# MKW38A4 register map
Vendor: NXP Semiconductors; Series: Kinetis_W; File version: 1.6
CPU: CM0PLUS r0p0, little endian, no MPU, no FPU, VTOR, 2 interrupt priority bits
Registers are 32-bit, read-write, no defined reset value unless marked. A register's access mark holds for its fields unless they carry their own. Offsets are from the block's base; [hi:lo] are bit positions; {n}, {i} and the like mark numbered series.

## XCVR_2P4GHZ_PHY — 2.4GHz PHY REGISTERS
Base 0x40087800
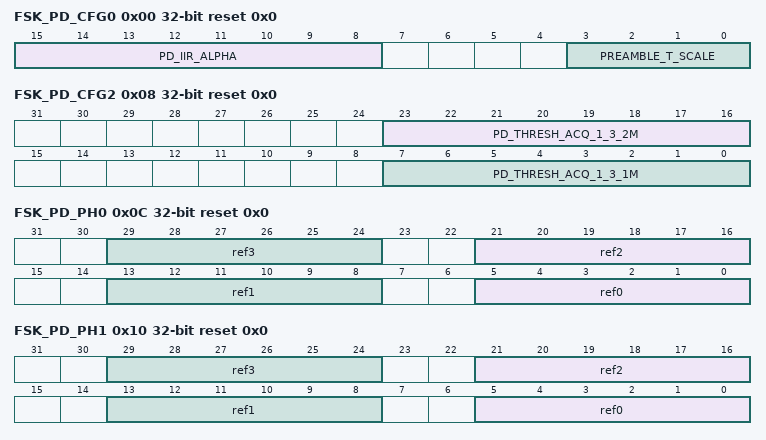
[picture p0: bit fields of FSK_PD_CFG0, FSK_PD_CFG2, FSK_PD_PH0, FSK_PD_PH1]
0x00 FSK_PD_CFG0 reset 0x0 — PHY Uncoded Preamble Detect Config 0
  [15:8] PD_IIR_ALPHA — Forgetting factor used by the complex correlations smoothing leaky integrator.
  [3:0] PREAMBLE_T_SCALE — Scaling factor used for fractional time estimation during preamble search.
0x04 FSK_PD_CFG1 reset 0x0 — PHY Uncoded Preamble Detect Config 1
  [7:0] PREAMBLE_PATTERN — 8-bit preamble pattern used in FM-domain preamble detector.
0x08 FSK_PD_CFG2 reset 0x0 — PHY Uncoded Preamble Detect Config 2
  [23:16] PD_THRESH_ACQ_1_3_2M — Preamble detect threshold for acq mode 1 and 3 at data rate 2Mbps
  [7:0] PD_THRESH_ACQ_1_3_1M — Preamble detect threshold for acq mode 1 and 3 at data rate 1Mbps
0x0C FSK_PD_PH0 reset 0x0
  [8n+5:8n] ref{n} (n=0..3) — Uncoded preamble reference waveform sample {n} (sfix6en5)
0x10 FSK_PD_PH1 reset 0x0
  [8n+5:8n] ref{n} (n=0..3) — Uncoded preamble reference waveform sample {n+4} (sfix6en5)
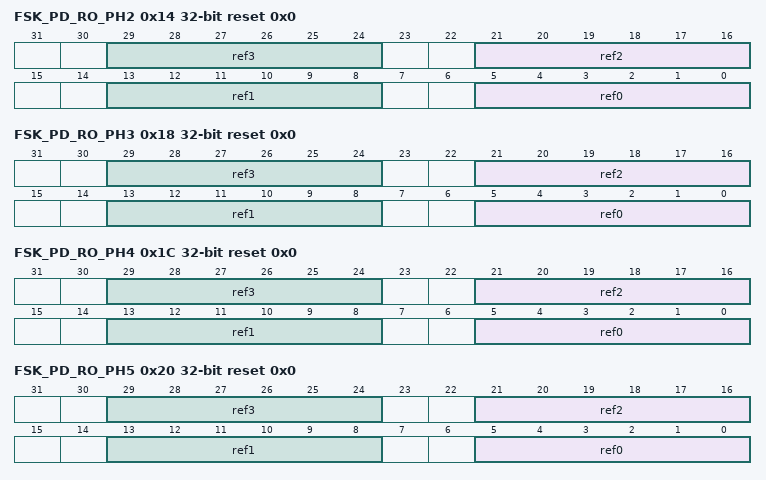
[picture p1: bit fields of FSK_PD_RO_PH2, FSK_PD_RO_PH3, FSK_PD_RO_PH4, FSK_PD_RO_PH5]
0x14 FSK_PD_RO_PH2 ro reset 0x0
  [8n+5:8n] ref{n} (n=0..3) — Uncoded preamble reference waveform sample {n+16} (sfix6en5)
0x18 FSK_PD_RO_PH3 ro reset 0x0
  [8n+5:8n] ref{n} (n=0..3) — Uncoded preamble reference waveform sample {n+20} (sfix6en5)
0x1C FSK_PD_RO_PH4 ro reset 0x0
  [8n+5:8n] ref{n} (n=0..3) — Uncoded preamble reference waveform sample {n+24} (sfix6en5)
0x20 FSK_PD_RO_PH5 ro reset 0x0
  [8n+5:8n] ref{n} (n=0..3) — Uncoded preamble reference waveform sample {n+28} (sfix6en5)
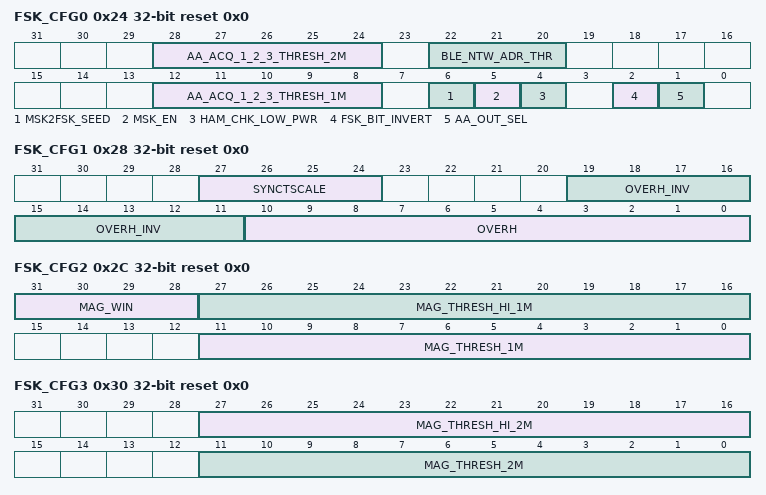
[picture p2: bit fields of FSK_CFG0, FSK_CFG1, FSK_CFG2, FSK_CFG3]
0x24 FSK_CFG0 reset 0x0 — PHY Uncoded Config 0
  [28:24] AA_ACQ_1_2_3_THRESH_2M — For 2Mbps data rate, correlation threshold applicable to AA detection; uses ufix5_En5 fixed-point format.
  [22:20] BLE_NTW_ADR_THR — Maximum hamming distance from the given AA pattern that may still be accepted as a match; valid range [0,7].
  [12:8] AA_ACQ_1_2_3_THRESH_1M — For 1Mbps data rate, Correlation threshold applicable to AA detection; uses ufix5_En5 fixed-point format.
  [6] MSK2FSK_SEED — Last bit of preamble.
  [5] MSK_EN — Configures PHY for MSK decoding.
  [4] HAM_CHK_LOW_PWR — Indicates whether hamming-distance check is applied at signal levels below mag_thresh_high;
    0=no; 1=yes
  [2] FSK_BIT_INVERT — This applies at the demodulator, so it affects both AA and the data portions of the packet.
    0=Normal demodulation; 1=Invert demodulated bits
  [1] AA_OUT_SEL — Specifies which AA bits to be played-back to the LL:
    0=output the received AA bits; 1=output the programmed AA bits
0x28 FSK_CFG1 reset 0x0 — PHY Uncoded Config 1
  [27:24] SYNCTSCALE — Scaling factor used for fractional time estimation during AA search; represented in ufix4_En3 format.
  [19:11] OVERH_INV — Reciprocal of modulation index; represented in ufix9_En7 format.
  [10:0] OVERH — Modulation index; represented in ufix11_En7 format.
0x2C FSK_CFG2 reset 0x0 — PHY Uncoded Config 2
  [31:28] MAG_WIN — Indicates the forgetting factor used in received signal level measurement;
  [27:16] MAG_THRESH_HI_1M — For 1Mbps data rate, the lowest signal level above which hamming-distance is always checked during AA detection; uses ufix12_En24 fixed-point format.
  [11:0] MAG_THRESH_1M — For 1Mbps data rate, the lowest signal level below which synchronization is considered unreliable and hence disallowed; uses ufix12_En24 fixed-point format.
0x30 FSK_CFG3 reset 0x0 — PHY Uncoded Config 3
  [27:16] MAG_THRESH_HI_2M — For 2Mbps data rate, the lowest signal level above which hamming-distance is always checked during AA detection; uses ufix12_En24 fixed-point format.
  [11:0] MAG_THRESH_2M — For 2Mbps data rate, the lowest signal level below which synchronization is considered unreliable and hence disallowed; uses ufix12_En24 fixed-point format.
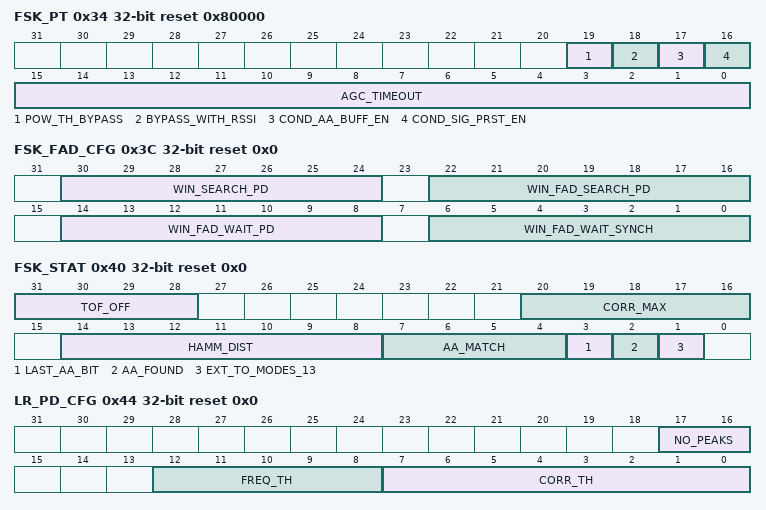
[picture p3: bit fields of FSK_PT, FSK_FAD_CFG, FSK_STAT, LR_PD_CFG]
0x34 FSK_PT reset 0x80000 — PHY Uncoded Power Threshold Config
  [19] POW_TH_BYPASS — Bypass power threshold when AGC gain are not set max;
    0=no bypass; 1=yes bypass
  [18] BYPASS_WITH_RSSI — Bypass signal power measurement with RSSI measurement;
    0=no; 1=yes
  [17] COND_AA_BUFF_EN — Enables special condition for enabling AA detector buffer;
    0=disable; 1=enable
  [16] COND_SIG_PRST_EN — Enables special conditioning of signal detection;
    0=disable; 1=enable
  [15:0] AGC_TIMEOUT — Time-out, applicable to special conditioning of signal power detection in the Power threshold block, after each AGC gain adjustment. It is expressed in number of samples.
0x38 FSK_FAD_CTRL reset 0x0 — PHY Uncoded FAD Control
  [0] FAD_EN — Enables FAD;
    0=disable; 1=enable
0x3C FSK_FAD_CFG reset 0x0 — PHY Uncoded FAD Config
  [30:24] WIN_SEARCH_PD — Time-window to match preamble pattern on samples coming from the currently selected antenna (refered to as T0 in the PHY state-machine section).
  [22:16] WIN_FAD_SEARCH_PD — Time-window to match preamble pattern on samples coming from the previously selected antenna (refered to as T1 in the PHY state-machine section).
  [14:8] WIN_FAD_WAIT_PD — Time-window to wait for clean samples if PD was not found after antenna switch (refered to as T2 in the PHY state-machine section).
  [6:0] WIN_FAD_WAIT_SYNCH — Time-window to wait for clean samples, before transitioning to AA search PHY state, if PD was found after antenna switch (refered to as T3 in the PHY state-machine section).
0x40 FSK_STAT ro reset 0x0 — PHY Uncoded Status
  [31:28] TOF_OFF — Timing offset for use in time-of-flight calculation.
  [20:16] CORR_MAX — Indicates the correlation witnessed when AA match occurred
  [14:8] HAMM_DIST — Indicates the hamming distance witnessed when AA match occurred.
  [7:4] AA_MATCH — Indicates which non-coded AA has matched. This will clear when the PHY is re-initialized.
  [3] LAST_AA_BIT — reserved
  [2] AA_FOUND — Indicates that a uncoded AA detect is active.
  [1] EXT_TO_MODES_13 — Reserved
0x44 LR_PD_CFG reset 0x0 — PHY Long Range Preamble Detect Config
  [17:16] NO_PEAKS — Number of consecutive correlation values that have to exceed the PD correlation threshold,for the same preamble phase, to assert preamble found;
    {v}={v+2} peaks; (v=0..3)
  [12:8] FREQ_TH — Threshold used to compare CFO estimates in the LR preamble detector; uses ufix5_En5 format.
  [7:0] CORR_TH — Correlation threshold applicable to preamble detection; uses (0,8,8) fixed-point format.
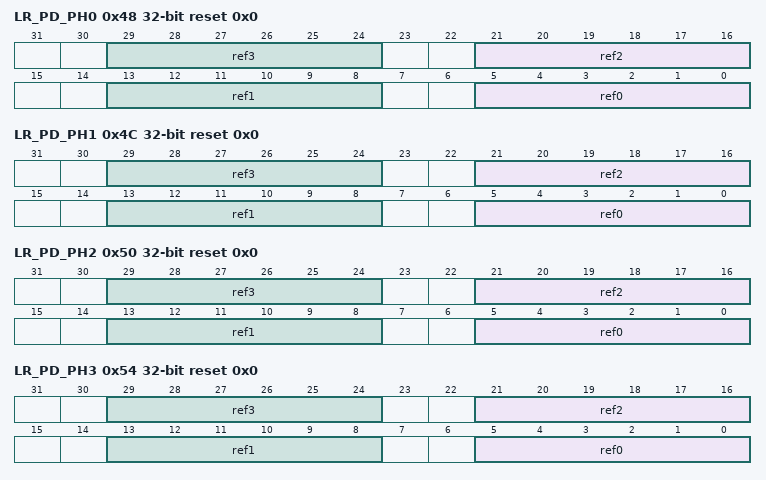
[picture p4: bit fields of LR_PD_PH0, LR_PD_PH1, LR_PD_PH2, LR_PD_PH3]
0x48 LR_PD_PH0 reset 0x0
  [8n+5:8n] ref{n} (n=0..3) — Long range preamble reference waveform sample {n} (sfix6en5)
0x4C LR_PD_PH1 reset 0x0
  [8n+5:8n] ref{n} (n=0..3) — Long range preamble reference waveform sample {n+4} (sfix6en5)
0x50 LR_PD_PH2 reset 0x0
  [8n+5:8n] ref{n} (n=0..3) — Long range preamble reference waveform sample {n+8} (sfix6en5)
0x54 LR_PD_PH3 reset 0x0
  [8n+5:8n] ref{n} (n=0..3) — Long range preamble reference waveform sample {n+12} (sfix6en5)
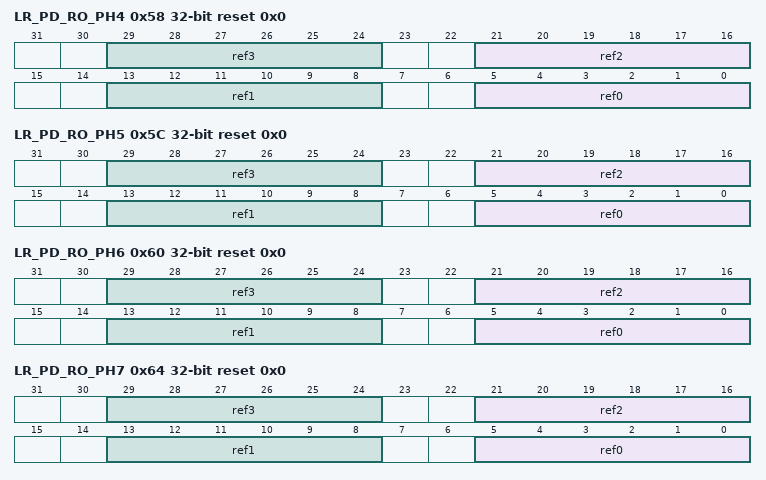
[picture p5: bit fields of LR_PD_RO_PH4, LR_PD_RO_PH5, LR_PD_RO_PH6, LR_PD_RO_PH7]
0x58 LR_PD_RO_PH4 ro reset 0x0
  [8n+5:8n] ref{n} (n=0..3) — Long range preamble reference waveform sample {n+16} (sfix6en5)
0x5C LR_PD_RO_PH5 ro reset 0x0
  [8n+5:8n] ref{n} (n=0..3) — Long range preamble reference waveform sample {n+20} (sfix6en5)
0x60 LR_PD_RO_PH6 ro reset 0x0
  [8n+5:8n] ref{n} (n=0..3) — Long range preamble reference waveform sample {n+24} (sfix6en5)
0x64 LR_PD_RO_PH7 ro reset 0x0
  [8n+5:8n] ref{n} (n=0..3) — Long range preamble reference waveform sample {n+28} (sfix6en5)
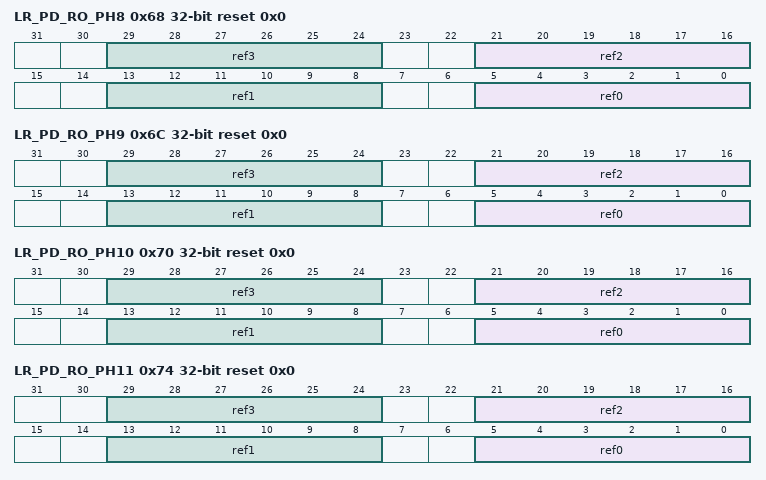
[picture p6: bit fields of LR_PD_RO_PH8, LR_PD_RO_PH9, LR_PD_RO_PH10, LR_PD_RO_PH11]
0x68 LR_PD_RO_PH8 ro reset 0x0
  [8n+5:8n] ref{n} (n=0..3) — Long range preamble reference waveform sample {n+32} (sfix6en5)
0x6C LR_PD_RO_PH9 ro reset 0x0
  [8n+5:8n] ref{n} (n=0..3) — Long range preamble reference waveform sample {n+36} (sfix6en5)
0x70 LR_PD_RO_PH10 ro reset 0x0
  [8n+5:8n] ref{n} (n=0..3) — Long range preamble reference waveform sample {n+40} (sfix6en5)
0x74 LR_PD_RO_PH11 ro reset 0x0
  [8n+5:8n] ref{n} (n=0..3) — Long range preamble reference waveform sample {n+44} (sfix6en5)
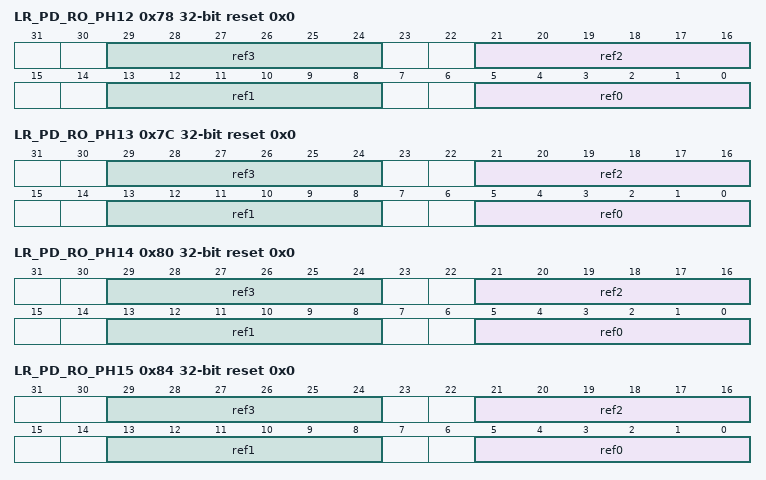
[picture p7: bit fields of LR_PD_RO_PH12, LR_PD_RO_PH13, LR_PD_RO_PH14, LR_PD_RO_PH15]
0x78 LR_PD_RO_PH12 ro reset 0x0
  [8n+5:8n] ref{n} (n=0..3) — Long range preamble reference waveform sample {n+48} (sfix6en5)
0x7C LR_PD_RO_PH13 ro reset 0x0
  [8n+5:8n] ref{n} (n=0..3) — Long range preamble reference waveform sample {n+52} (sfix6en5)
0x80 LR_PD_RO_PH14 ro reset 0x0
  [8n+5:8n] ref{n} (n=0..3) — Long range preamble reference waveform sample {n+56} (sfix6en5)
0x84 LR_PD_RO_PH15 ro reset 0x0
  [8n+5:8n] ref{n} (n=0..3) — Long range preamble reference waveform sample {n+60} (sfix6en5)
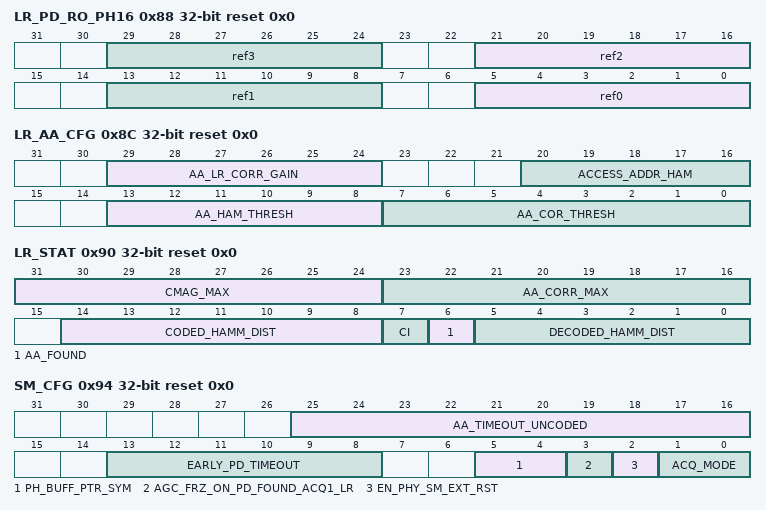
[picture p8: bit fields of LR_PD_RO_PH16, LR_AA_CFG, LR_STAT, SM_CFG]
0x88 LR_PD_RO_PH16 ro reset 0x0
  [8n+5:8n] ref{n} (n=0..3) — Long range preamble reference waveform sample {n+64} (sfix6en5)
0x8C LR_AA_CFG reset 0x0 — PHY Long Range AA Config
  [29:24] AA_LR_CORR_GAIN — AA correlator gain. Format ufix6en3. This gain is applied to soft bits from the demodulator before they are used for address search synchronization.
  [20:16] ACCESS_ADDR_HAM — Threshold use to compare the Hamming distance, between the reference AA sequence and the received Viterbi decoded AA sequence.
  [13:8] AA_HAM_THRESH — Threshold use to compare the Hamming distance, between reference coded sequence and received coded sequence, in the long-range AA correlator.
  [7:0] AA_COR_THRESH — Threshold use to compare the correlation magnitude in the long-range AA correlator.
0x90 LR_STAT ro reset 0x0 — PHY Long Range Status
  [31:24] CMAG_MAX — Indicates the maximum preamble correlation magnitude during preamble found
  [23:16] AA_CORR_MAX — Indicates the AA correlation magnitude witnessed when AA match occurred
  [14:8] CODED_HAMM_DIST — Hamming distance between the coded reference sequence and the coded received sequence.
  [7] CI — CI received.
  [6] AA_FOUND — Indicates that a AA detect is active for both LR and uncoded.
  [5:0] DECODED_HAMM_DIST — Hamming distance between the reference sequence and the Viterbi decoded received sequence
0x94 SM_CFG reset 0x0 — PHY State Machine Config
  [25:16] AA_TIMEOUT_UNCODED — Time-out value for access address search for uncoded packets
  [13:8] EARLY_PD_TIMEOUT — Time-out used to reset the AGC state-machine for the eventuality that an "PD found early" event occurs but it is not followed by an "PD found" event
  [5:4] PH_BUFF_PTR_SYM — Phase buffer size to demodulator, long range only.
  [3] AGC_FRZ_ON_PD_FOUND_ACQ1_LR — Specfies AGC freeze condition for non-coded acq.1 and Bluetooth LE long range.
    0=AGC freeze on AA found; 1=AGC freeze asserted on PD found
  [2] EN_PHY_SM_EXT_RST — Reserved, should keep 0.
  [1:0] ACQ_MODE — Acquisition mode for non-coded reception
    1=Use preamble and verify a correlation peak, the synch at the symbol rate as symbol timing is established by the preamble acquisition; 2=Use synch only (which may incorporate part of the preamble); 3=Use mainly the sync detection: Use a low threshold on the preamble detector and launch the synch detection only if the preamble has shown a recent peak
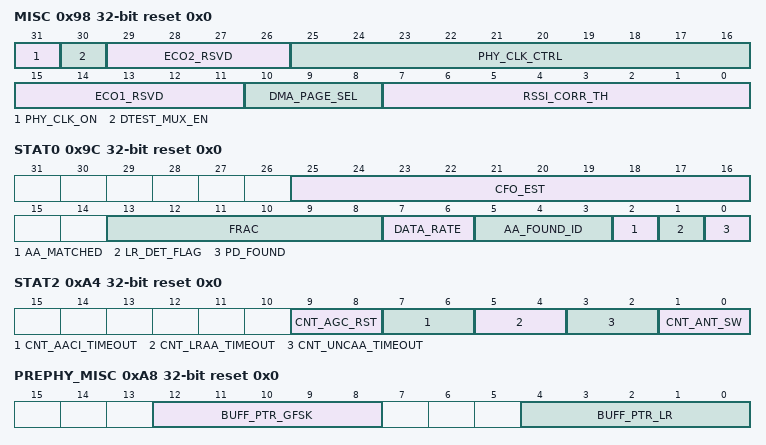
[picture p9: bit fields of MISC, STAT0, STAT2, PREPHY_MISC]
0x98 MISC reset 0x0 — PHY Misc Config
  [31] PHY_CLK_ON — Force PHY clock ON
  [30] DTEST_MUX_EN — Reserved. Should be programed as reset value 0.
  [29:26] ECO2_RSVD — Reserved
  [25:16] PHY_CLK_CTRL — Enables various clock gating features. Bits are individually decoded, so any combination is allowable.
  [15:11] ECO1_RSVD — Reserved. Must be programed as reset value 0.
  [10:8] DMA_PAGE_SEL — Select which DMA page is send out
    0=Select DMA PAGE 0 for M3C with cfo;; 1=Select DMA PAGE 1 for M3C with magnitude;; 2=Select DMA PAGE 2 for un-coded;; 3=Select DMA PAGE 3 for Long Range Preampble Detect;; 4=Select DMA PAGE 4 for Long Range AA Detect;
  [7:0] RSSI_CORR_TH — Threshold use to compare a correlation magnitude value, computed in the acquisition block, in order to determine the correlation flag value provided by the PHY to the LQI computation block. Format is ufix8_En8
0x9C STAT0 ro reset 0x0 — PHY Status 0
  [25:16] CFO_EST — Indicates the currently estimated CFO. Format is sfix10_en9(sign extend form sfix8_en9)
  [13:8] FRAC — Indicates the fractional timing estimate determined in the acquisition block. Format is sfix6_en5(sign extend from sfix3_En2).
  [7:6] DATA_RATE — Indicates the data rate of received bit
    0=1Mbps; 1=2Mbps; 2=125kbps; 3=500kbps
  [5:3] AA_FOUND_ID — Indicates which AA was matched for LR and uncode
    {v}=uncoded address {v} matched (v=0..3); 4=long range address matched
  [2] AA_MATCHED — Indicates AA was matched for LR or uncoded
  [1] LR_DET_FLAG — Indicates Bluetooth LE long range was detected
  [0] PD_FOUND — PD_FOUND for LR or uncoded
0xA0 STAT1 ro reset 0x0 — PHY Status 1
  [31:0] AA_BITS — AA bits either received or programed
0xA4 STAT2 ro reset 0x0 — PHY Status 2
  [9:8] CNT_AGC_RST — Count of AGC soft reset event
  [7:6] CNT_AACI_TIMEOUT — Count of long range AACI detect timeout event
  [5:4] CNT_LRAA_TIMEOUT — Count of lang range AA search timeout event
  [3:2] CNT_UNCAA_TIMEOUT — Count of uncoded AA search timeout event
  [1:0] CNT_ANT_SW — Count of uncoded ANT switch event when FAD was enabled.
0xA8 PREPHY_MISC reset 0x0 — PHY PrePHY Misc Config
  [12:8] BUFF_PTR_GFSK — Pointer to the PrePHY IQ buffer for the reception of the uncoded packets.
  [4:0] BUFF_PTR_LR — Pointer to the PrePHY IQ buffer for the reception of the long-range packets.
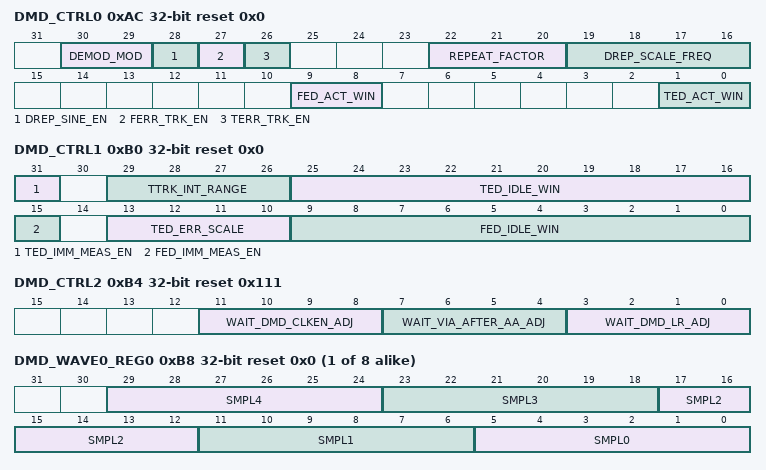
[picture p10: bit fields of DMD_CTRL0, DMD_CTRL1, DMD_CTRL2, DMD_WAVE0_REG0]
0xAC DMD_CTRL0 reset 0x0 — PHY Demodulator Control 0
  [30:29] DEMOD_MOD — Determines the number of taps used by the demodulator correlators;
    0=use 12 taps; 1=use 4 taps; 2=use 7 taps; 3=use 13 taps
  [28] DREP_SINE_EN — Flag used to enable the non-linear operation in the de-repeater.
  [27] FERR_TRK_EN — Enables frequency tracking in the demodulator.
  [26] TERR_TRK_EN — Enables time tracking in the demodulator.
  [22:20] REPEAT_FACTOR — Repetition factor used by the de-repeater.
  [19:16] DREP_SCALE_FREQ — Frequency domain signal scaling factor used by the de-repeater.
  [9:8] FED_ACT_WIN — Active window size for the frequency tracking mechanism, expressed in symbols.
  [1:0] TED_ACT_WIN — Active window size for the time tracking mechanism, expressed in symbols.
0xB0 DMD_CTRL1 reset 0x0 — PHY Dmodulator Control 1
  [31] TED_IMM_MEAS_EN — Specifies whether the time tracking starts with an active window;
    0=start with idle window; 1=start with active window
  [29:26] TTRK_INT_RANGE — Timing error correction interpolation range, expressed in samples. The value must equal or bigger than 1.
  [25:16] TED_IDLE_WIN — Idle window size for the time tracking mechanism, expressed in symbols.
  [15] FED_IMM_MEAS_EN — Specifies whether the frequency tracking starts with an active window;
    0=start with idle window; 1=start with active window
  [13:10] TED_ERR_SCALE — Scaling factor used by the time tracking loop.
  [9:0] FED_IDLE_WIN — Idle window size for the frequency tracking mechanism, expressed in symbols.
0xB4 DMD_CTRL2 reset 0x111 — PHY Demodulator Control 2
  [11:8] WAIT_DMD_CLKEN_ADJ — Reserved. Must be programed as reset value 1.
  [7:4] WAIT_VIA_AFTER_AA_ADJ — Reserved. Must be programed as reset value 1.
  [3:0] WAIT_DMD_LR_ADJ — Reserved. Must be programed as reset value 1.
{0xB8+0xC*i} DMD_WAVE{i}_REG0 reset 0x0 (i=0..7)
  [6n+5:6n] SMPL{n} (n=0..4) — Demodulator waveform {i} sample {n} (sfix6en5)
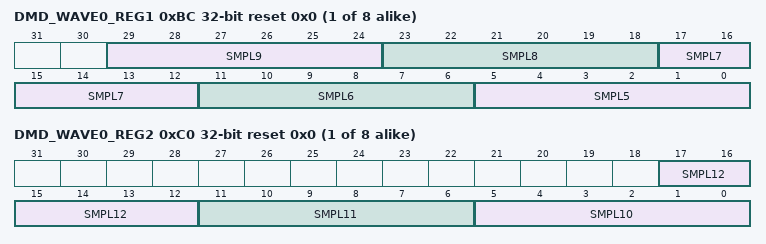
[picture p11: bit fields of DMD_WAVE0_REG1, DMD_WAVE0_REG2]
{0xBC+0xC*i} DMD_WAVE{i}_REG1 reset 0x0 (i=0..7)
  [6n-25:6n-30] SMPL{n} (n=5..9) — Demodulator waveform {i} sample {n} (sfix6en5)
{0xC0+0xC*i} DMD_WAVE{i}_REG2 reset 0x0 (i=0..7)
  [17:12] SMPL12 — Demodulator waveform {i} sample 12 (sfix6en5)
  [11:6] SMPL11 — Demodulator waveform {i} sample 11 (sfix6en5)
  [5:0] SMPL10 — Demodulator waveform {i} sample 10 (sfix6en5)
